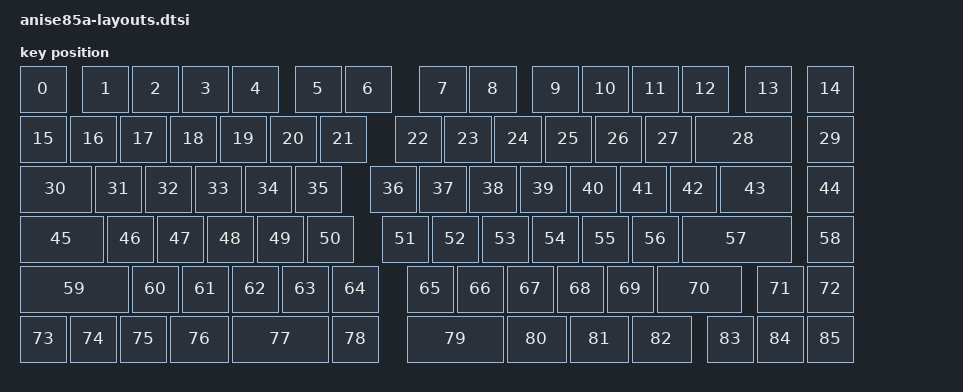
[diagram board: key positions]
#include <physical_layouts.dtsi>

/*
 * Generated by tools/make_layouts.py from anisehid/anise-kbd desc-gen/desc/anise85a.json.
 * Order matches default_transform in anise85a.dtsi.
 */

/ {
    anise85a_layout: anise85a_layout {
        compatible = "zmk,physical-layout";
        display-name = "Anise85A";

        keys  //                     w   h    x    y  rot  rx  ry
            = <&key_physical_attrs 100 100    0    0    0   0   0>
            , <&key_physical_attrs 100 100  125    0    0   0   0>
            , <&key_physical_attrs 100 100  225    0    0   0   0>
            , <&key_physical_attrs 100 100  325    0    0   0   0>
            , <&key_physical_attrs 100 100  425    0    0   0   0>
            , <&key_physical_attrs 100 100  550    0    0   0   0>
            , <&key_physical_attrs 100 100  650    0    0   0   0>
            , <&key_physical_attrs 100 100  800    0    0   0   0>
            , <&key_physical_attrs 100 100  900    0    0   0   0>
            , <&key_physical_attrs 100 100 1025    0    0   0   0>
            , <&key_physical_attrs 100 100 1125    0    0   0   0>
            , <&key_physical_attrs 100 100 1225    0    0   0   0>
            , <&key_physical_attrs 100 100 1325    0    0   0   0>
            , <&key_physical_attrs 100 100 1450    0    0   0   0>
            , <&key_physical_attrs 100 100 1575    0    0   0   0>
            , <&key_physical_attrs 100 100    0  100    0   0   0>
            , <&key_physical_attrs 100 100  100  100    0   0   0>
            , <&key_physical_attrs 100 100  200  100    0   0   0>
            , <&key_physical_attrs 100 100  300  100    0   0   0>
            , <&key_physical_attrs 100 100  400  100    0   0   0>
            , <&key_physical_attrs 100 100  500  100    0   0   0>
            , <&key_physical_attrs 100 100  600  100    0   0   0>
            , <&key_physical_attrs 100 100  750  100    0   0   0>
            , <&key_physical_attrs 100 100  850  100    0   0   0>
            , <&key_physical_attrs 100 100  950  100    0   0   0>
            , <&key_physical_attrs 100 100 1050  100    0   0   0>
            , <&key_physical_attrs 100 100 1150  100    0   0   0>
            , <&key_physical_attrs 100 100 1250  100    0   0   0>
            , <&key_physical_attrs 200 100 1350  100    0   0   0>
            , <&key_physical_attrs 100 100 1575  100    0   0   0>
            , <&key_physical_attrs 150 100    0  200    0   0   0>
            , <&key_physical_attrs 100 100  150  200    0   0   0>
            , <&key_physical_attrs 100 100  250  200    0   0   0>
            , <&key_physical_attrs 100 100  350  200    0   0   0>
            , <&key_physical_attrs 100 100  450  200    0   0   0>
            , <&key_physical_attrs 100 100  550  200    0   0   0>
            , <&key_physical_attrs 100 100  700  200    0   0   0>
            , <&key_physical_attrs 100 100  800  200    0   0   0>
            , <&key_physical_attrs 100 100  900  200    0   0   0>
            , <&key_physical_attrs 100 100 1000  200    0   0   0>
            , <&key_physical_attrs 100 100 1100  200    0   0   0>
            , <&key_physical_attrs 100 100 1200  200    0   0   0>
            , <&key_physical_attrs 100 100 1300  200    0   0   0>
            , <&key_physical_attrs 150 100 1400  200    0   0   0>
            , <&key_physical_attrs 100 100 1575  200    0   0   0>
            , <&key_physical_attrs 175 100    0  300    0   0   0>
            , <&key_physical_attrs 100 100  175  300    0   0   0>
            , <&key_physical_attrs 100 100  275  300    0   0   0>
            , <&key_physical_attrs 100 100  375  300    0   0   0>
            , <&key_physical_attrs 100 100  475  300    0   0   0>
            , <&key_physical_attrs 100 100  575  300    0   0   0>
            , <&key_physical_attrs 100 100  725  300    0   0   0>
            , <&key_physical_attrs 100 100  825  300    0   0   0>
            , <&key_physical_attrs 100 100  925  300    0   0   0>
            , <&key_physical_attrs 100 100 1025  300    0   0   0>
            , <&key_physical_attrs 100 100 1125  300    0   0   0>
            , <&key_physical_attrs 100 100 1225  300    0   0   0>
            , <&key_physical_attrs 225 100 1325  300    0   0   0>
            , <&key_physical_attrs 100 100 1575  300    0   0   0>
            , <&key_physical_attrs 225 100    0  400    0   0   0>
            , <&key_physical_attrs 100 100  225  400    0   0   0>
            , <&key_physical_attrs 100 100  325  400    0   0   0>
            , <&key_physical_attrs 100 100  425  400    0   0   0>
            , <&key_physical_attrs 100 100  525  400    0   0   0>
            , <&key_physical_attrs 100 100  625  400    0   0   0>
            , <&key_physical_attrs 100 100  775  400    0   0   0>
            , <&key_physical_attrs 100 100  875  400    0   0   0>
            , <&key_physical_attrs 100 100  975  400    0   0   0>
            , <&key_physical_attrs 100 100 1075  400    0   0   0>
            , <&key_physical_attrs 100 100 1175  400    0   0   0>
            , <&key_physical_attrs 175 100 1275  400    0   0   0>
            , <&key_physical_attrs 100 100 1475  400    0   0   0>
            , <&key_physical_attrs 100 100 1575  400    0   0   0>
            , <&key_physical_attrs 100 100    0  500    0   0   0>
            , <&key_physical_attrs 100 100  100  500    0   0   0>
            , <&key_physical_attrs 100 100  200  500    0   0   0>
            , <&key_physical_attrs 125 100  300  500    0   0   0>
            , <&key_physical_attrs 200 100  425  500    0   0   0>
            , <&key_physical_attrs 100 100  625  500    0   0   0>
            , <&key_physical_attrs 200 100  775  500    0   0   0>
            , <&key_physical_attrs 125 100  975  500    0   0   0>
            , <&key_physical_attrs 125 100 1100  500    0   0   0>
            , <&key_physical_attrs 125 100 1225  500    0   0   0>
            , <&key_physical_attrs 100 100 1375  500    0   0   0>
            , <&key_physical_attrs 100 100 1475  500    0   0   0>
            , <&key_physical_attrs 100 100 1575  500    0   0   0>
            ;
    };
};
